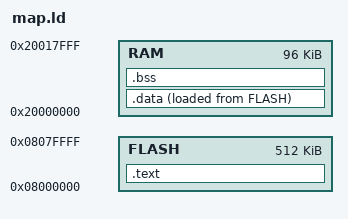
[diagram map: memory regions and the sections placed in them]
MEMORY
{
    FLASH : ORIGIN = 0x08000000, LENGTH = 512K
    RAM : ORIGIN = 0x20000000, LENGTH = 96K
}


SECTIONS
{
    .text : {
        _stext = .;
        *(.vectors*)
        *(.text*)
        *(.rodata*)
        *(.rodata.*)
        _etext = .;
    } > FLASH

    .data : ALIGN(4) {
        _sdata = .;
        _sidata = LOADADDR(.data);
        *(.data*)
        . = ALIGN(4);
        _edata = .;

    } > RAM AT > FLASH

    .bss : ALIGN(4) {
        _sbss = .;
        *(.bss*)
        . = ALIGN(4);
        _ebss = .;
    } > RAM

    __StackTop = ORIGIN(RAM) + LENGTH(RAM);
    PROVIDE(__stack = __StackTop - 4);
}
